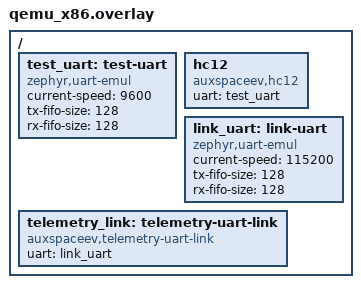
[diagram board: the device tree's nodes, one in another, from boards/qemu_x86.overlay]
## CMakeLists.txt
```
# Copyright (c) 2026 Auxspace e.V.
# SPDX-License-Identifier: Apache-2.0

cmake_minimum_required(VERSION 3.20.0)
find_package(Zephyr REQUIRED HINTS $ENV{ZEPHYR_BASE})
project(aurora_lib_telemetry_test)

FILE(GLOB app_sources src/*.c)
target_sources(app PRIVATE ${app_sources})
```

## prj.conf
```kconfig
CONFIG_ZTEST=y

CONFIG_AURORA_TELEMETRY=y
CONFIG_AURORA_TELEMETRY_UART_LINK=y

# Emulated UART for the HC-12 backend: keeps frame bytes off the real
# uart0 that carries ztest output. UART_EMUL depends on the broader
# EMUL framework, so both have to be enabled explicitly.
CONFIG_EMUL=y
CONFIG_UART_EMUL=y

# Pin the rate-limit window so the rate-limiter test exercises real
# state without being timing-fragile.
CONFIG_AURORA_TELEMETRY_HC12_MIN_INTERVAL_MS=50

# The state machine isn't actually used here, but the telemetry API
# pulls in sm_state / sm_inputs from its header.
CONFIG_AURORA_STATE_MACHINE=y
```

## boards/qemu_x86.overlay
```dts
/*
 * Copyright (c) 2026 Auxspace e.V.
 * SPDX-License-Identifier: Apache-2.0
 *
 * Route the HC-12 backend to Zephyr's emulated UART driver so the
 * TX worker's frame bytes don't collide with ztest output on the
 * real qemu uart0. The AT helper is not exercised here, so the SET
 * GPIO and uart_configure() support are intentionally absent.
 */

/ {
	test_uart: test-uart {
		compatible = "zephyr,uart-emul";
		status = "okay";
		current-speed = <9600>;
		tx-fifo-size = <128>;
		rx-fifo-size = <128>;
	};

	hc12: hc12 {
		compatible = "auxspaceev,hc12";
		uart = <&test_uart>;
		status = "okay";
	};

	/* A second emulated UART carries the plain uart-link backend, so a
	 * run exercises both instances of the uart-link engine at once and
	 * the dispatcher really does fan out to two independent transports
	 * - which is what a brain board with a local radio and an AUX-Tel
	 * relay above it looks like.
	 */
	link_uart: link-uart {
		compatible = "zephyr,uart-emul";
		status = "okay";
		current-speed = <115200>;
		tx-fifo-size = <128>;
		rx-fifo-size = <128>;
	};

	telemetry_link: telemetry-uart-link {
		compatible = "auxspaceev,telemetry-uart-link";
		uart = <&link_uart>;
		status = "okay";
	};
};
```

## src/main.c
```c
/**
 * @file main.c
 * @brief Unit tests for the telemetry dispatcher and its UART backends.
 *
 * Three suites:
 *   - format:    locks the telemetry wire frame byte-for-byte.
 *   - rate:      exercises the uart-link rate limiter (through the
 *                HC-12 backend, which is one instance of it).
 *   - dispatch:  verifies fan-out to multiple registered backends and
 *                the dispatcher's error aggregation, for SM updates
 *                and STATUS heartbeats.
 *
 * UART traffic from the worker thread is dumped into an emulated UART
 * rather than qemu's uart0, which carries ztest output. Tests never
 * read what leaves the wire. They verify counters and frame bytes
 * built by the shared helper directly.
 *
 * Copyright (c) 2025-2026 Auxspace e.V.
 *
 * SPDX-License-Identifier: Apache-2.0
 */

#include <string.h>

#include <zephyr/kernel.h>
#include <zephyr/sys/byteorder.h>
#include <zephyr/sys/crc.h>
#include <zephyr/ztest.h>

#include <aurora/lib/telemetry.h>
#include <aurora/lib/telemetry/wire.h>

/* ==========================================================
 *                     STUB BACKENDS
 * ==========================================================
 * Two stub backends are registered at link time alongside the HC-12
 * backend. Their behaviour is controlled by these globals so each
 * test can configure return codes independently.
 */
static int  stub_a_init_calls;
static int  stub_a_send_calls;
static int  stub_a_init_rc;
static int  stub_a_send_rc;

static int  stub_a_status_calls;
static struct telemetry_status stub_a_last_status;

static int  stub_b_init_calls;
static int  stub_b_send_calls;
static int  stub_b_init_rc;
static int  stub_b_send_rc;

static int stub_a_init(void) { stub_a_init_calls++; return stub_a_init_rc; }
static int stub_a_send(enum sm_state s, enum sm_type type,
		       const struct sm_inputs *in)
{
	ARG_UNUSED(s); ARG_UNUSED(in);
	stub_a_send_calls++;
	return stub_a_send_rc;
}

/* Only stub A implements send_status, so the dispatcher's NULL-slot
 * skip is exercised by stub B.
 */
static int stub_a_status(const struct telemetry_status *st)
{
	stub_a_status_calls++;
	stub_a_last_status = *st;
	return stub_a_send_rc;
}

static int stub_b_init(void) { stub_b_init_calls++; return stub_b_init_rc; }
static int stub_b_send(enum sm_state s, enum sm_type type,
		       const struct sm_inputs *in)
{
	ARG_UNUSED(s); ARG_UNUSED(in);
	stub_b_send_calls++;
	return stub_b_send_rc;
}

static const struct telemetry_backend_api stub_a_api = {
	.init = stub_a_init, .send_sm_update = stub_a_send,
	.send_status = stub_a_status,
};
static const struct telemetry_backend_api stub_b_api = {
	.init = stub_b_init, .send_sm_update = stub_b_send,
};

TELEMETRY_BACKEND_DEFINE(stub_a, &stub_a_api);
TELEMETRY_BACKEND_DEFINE(stub_b, &stub_b_api);

static void stub_reset(void)
{
	stub_a_init_calls = 0; stub_a_send_calls = 0;
	stub_a_init_rc = 0;    stub_a_send_rc = 0;
	stub_a_status_calls = 0;
	memset(&stub_a_last_status, 0, sizeof(stub_a_last_status));
	stub_b_init_calls = 0; stub_b_send_calls = 0;
	stub_b_init_rc = 0;    stub_b_send_rc = 0;
}

/* Minimal valid SM inputs for send_sm_update calls. */
static const struct sm_inputs DUMMY_INPUTS = {
	.armed = 1,
	.altitude = 100.0,
	.acceleration = 9.81,
	.accel_vert = 1.0,
	.velocity = 12.5,
	.orientation = { 0.1, 0.2, 0.3 },
};

/* Sleep long enough to clear any rate-limit window left over from a
 * previous test. CONFIG_AURORA_TELEMETRY_HC12_MIN_INTERVAL_MS=50.
 */
static inline void clear_rate_window(void)
{
	k_msleep(60);
}

/* ==========================================================
 *                     FORMAT SUITE
 * ==========================================================
 * Locks the HC-12 wire frame layout. Magic bytes, header field
 * positions, and the CRC algorithm are hardcoded *in the test*
 * rather than imported from the backend's headers. A silent change
 * to any of them in production must fail this suite.
 */

ZTEST(telemetry_wire_format, test_sm_update_frame_bytes)
{
	struct telemetry_wire_sm_update p = {
		.timestamp_ms = 0xDEADBEEF,
		.state        = 3,
		.armed        = 1,
		.reserved     = 0,
		.altitude     = 123.5,
		.acceleration = 9.81,
		.accel_vert   = -1.25,
		.velocity     = 42.0,
		.orientation  = { 0.5, -0.25, 1.0 },
	};

	uint8_t buf[128] = { 0 };
	size_t  n = telemetry_wire_finalise(buf, sizeof(buf), 0x01, &p,
					    (uint8_t)sizeof(p));

	/* Total = 2 magic + 1 type + 1 len + 64 payload + 2 CRC = 70.
	 * Payload = u32 + u8 + u8 + i16 + 4*f64 + 3*f64 = 64 bytes
	 * (packed, little-endian).
	 */
	zassert_equal(n, 70, "unexpected frame length: %zu", n);

	zassert_equal(buf[0], 0xA5, "magic0");
	zassert_equal(buf[1], 0x5A, "magic1");
	zassert_equal(buf[2], 0x01, "type=SM_UPDATE");
	zassert_equal(buf[3], 64,   "payload length byte");

	/* Payload is little-endian, packed. Check the first u32 by hand
	 * to lock byte order; trust memcpy semantics for the rest.
	 */
	zassert_equal(buf[4], 0xEF, "ts byte 0 (LE)");
	zassert_equal(buf[5], 0xBE, "ts byte 1");
	zassert_equal(buf[6], 0xAD, "ts byte 2");
	zassert_equal(buf[7], 0xDE, "ts byte 3");
	zassert_equal(buf[8], 3,    "state byte");
	zassert_equal(buf[9], 1,    "armed byte");

	/* CRC-16/CCITT (init 0xFFFF) over [type .. end of payload]. */
	uint16_t expected_crc = crc16_ccitt(0xFFFF, &buf[2], 1 + 1 + 64);
	uint16_t actual_crc   = sys_get_le16(&buf[68]);
	zassert_equal(actual_crc, expected_crc,
		      "CRC mismatch: got %04x want %04x",
		      actual_crc, expected_crc);
}

ZTEST(telemetry_wire_format, test_status_frame_bytes)
{
	struct telemetry_wire_status p = {
		.timestamp_ms = 0x01020304,
		.state        = 0,
		.sm_type      = 0,
		.flags        = 0x1B,
	};

	uint8_t buf[32] = { 0 };
	size_t  n = telemetry_wire_finalise(buf, sizeof(buf), 0x02, &p,
					    (uint8_t)sizeof(p));

	/* Total = 4 header + 8 payload + 2 CRC = 14. */
	zassert_equal(n, 14, "unexpected frame length: %zu", n);
	zassert_equal(buf[2], 0x02, "type=STATUS");
	zassert_equal(buf[3], 8,    "payload length byte");
	zassert_equal(buf[4], 0x04, "ts byte 0 (LE)");
	zassert_equal(buf[7], 0x01, "ts byte 3");
	zassert_equal(buf[8], 0,    "state byte");
	zassert_equal(buf[9], 0,    "sm_type byte");
	zassert_equal(buf[10], 0x1B, "flags byte");
	zassert_equal(buf[11], 0,   "reserved byte");

	/* Flag bits are decoded by offset on the ground: lock them. */
	zassert_equal(AURORA_TELEMETRY_WIRE_TYPE_STATUS, 0x02, "type id");
	zassert_equal(AURORA_TELEMETRY_WIRE_STATUS_ARMED, 0x01, "armed bit");
	zassert_equal(AURORA_TELEMETRY_WIRE_STATUS_IMU_OK, 0x02, "imu bit");
	zassert_equal(AURORA_TELEMETRY_WIRE_STATUS_BARO_OK, 0x04, "baro bit");
	zassert_equal(AURORA_TELEMETRY_WIRE_STATUS_CALIBRATED, 0x08, "cal bit");
	zassert_equal(AURORA_TELEMETRY_WIRE_STATUS_LOG_READY, 0x10, "log bit");

	zassert_true(telemetry_wire_validate(buf, n), "status frame validates");
}

ZTEST(telemetry_wire_format, test_buffer_too_small)
{
	struct telemetry_wire_sm_update p = { 0 };
	uint8_t small[10];

	zassert_equal(telemetry_wire_finalise(small, sizeof(small), 0x01, &p,
					      (uint8_t)sizeof(p)),
		      0, "should reject undersized buffer");
}

/* A zero-length payload is a valid frame: header plus CRC only. The
 * AUX-Tel relay forwards types it does not know, so an empty payload
 * has to survive the round trip.
 */
ZTEST(telemetry_wire_format, test_empty_payload_frame)
{
	uint8_t buf[16] = { 0 };
	size_t n = telemetry_wire_finalise(buf, sizeof(buf), 0x42, NULL, 0);

	zassert_equal(n, 6, "empty frame should be 6 bytes, got %zu", n);
	zassert_equal(buf[3], 0, "payload length byte");

	uint16_t expected = crc16_ccitt(0xFFFF, &buf[2], 2);

	zassert_equal(sys_get_le16(&buf[4]), expected, "CRC over type+len");
}

/* The relay reconstructs the CRC from the frame it received, so the
 * helper's span must match what a receiver computes by hand.
 */
ZTEST(telemetry_wire_format, test_crc_helper_matches_manual_span)
{
	struct telemetry_wire_sm_update p = { .timestamp_ms = 1, .state = 2 };
	uint8_t buf[128] = { 0 };
	size_t n = telemetry_wire_finalise(buf, sizeof(buf), 0x01, &p,
					   (uint8_t)sizeof(p));

	zassert_equal(n, 70, "frame length");
	zassert_equal(telemetry_wire_crc(buf, (uint8_t)sizeof(p)),
		      crc16_ccitt(0xFFFF, &buf[2], sizeof(p) + 2),
		      "helper span differs from the manual span");
}

/* telemetry_wire_validate() is the gate every frame arriving off the air
 * passes through, and it runs on a buffer straight out of a radio - so
 * the cases that matter are the malformed ones. A corrupt length byte in
 * particular must be caught before the CRC helper is allowed to read a
 * span derived from it.
 */
ZTEST(telemetry_wire_format, test_validate_accepts_a_built_frame)
{
	struct telemetry_wire_sm_update payload = {
		.timestamp_ms = 0x11223344,
		.state = 3,
		.armed = 1,
		.altitude = 1234.5,
	};
	uint8_t buf[128] = { 0 };
	size_t n = telemetry_wire_finalise(buf, sizeof(buf), 0x01, &payload,
					   (uint8_t)sizeof(payload));

	zassert_equal(n, 70, "frame length");
	zassert_true(telemetry_wire_validate(buf, n),
		     "a frame from telemetry_wire_finalise() must validate");
}

ZTEST(telemetry_wire_format, test_validate_accepts_empty_payload)
{
	uint8_t buf[16] = { 0 };
	size_t n = telemetry_wire_finalise(buf, sizeof(buf), 0x7F, NULL, 0);

	zassert_equal(n, AURORA_TELEMETRY_WIRE_OVERHEAD, "frame length");
	zassert_true(telemetry_wire_validate(buf, n), "empty payload frame");
}

ZTEST(telemetry_wire_format, test_validate_rejects_bad_magic)
{
	uint8_t buf[32] = { 0 };
	size_t n = telemetry_wire_finalise(buf, sizeof(buf), 0x01, "abcd", 4);

	buf[0] ^= 0xFF;
	zassert_false(telemetry_wire_validate(buf, n), "corrupt magic0");

	buf[0] ^= 0xFF;
	buf[1] ^= 0xFF;
	zassert_false(telemetry_wire_validate(buf, n), "corrupt magic1");
}

ZTEST(telemetry_wire_format, test_validate_rejects_length_disagreement)
{
	uint8_t buf[32] = { 0 };
	size_t n = telemetry_wire_finalise(buf, sizeof(buf), 0x01, "abcd", 4);

	/* The frame is intact, but the transport claims a different size:
	 * a truncated or padded packet.
	 */
	zassert_false(telemetry_wire_validate(buf, n - 1), "short packet");
	zassert_false(telemetry_wire_validate(buf, n + 1), "long packet");

	/* And the mirror image: the right byte count, but a len byte that
	 * disagrees with it. Left unchecked this is an out-of-bounds read.
	 */
	buf[3] = 200;
	zassert_false(telemetry_wire_validate(buf, n), "corrupt len byte");
}

ZTEST(telemetry_wire_format, test_validate_rejects_runts)
{
	uint8_t buf[AURORA_TELEMETRY_WIRE_OVERHEAD] = {
		AURORA_TELEMETRY_WIRE_MAGIC0, AURORA_TELEMETRY_WIRE_MAGIC1,
	};

	for (size_t len = 0; len < AURORA_TELEMETRY_WIRE_OVERHEAD; len++) {
		zassert_false(telemetry_wire_validate(buf, len),
			      "accepted a %zu byte packet", len);
	}

	zassert_false(telemetry_wire_validate(NULL, 70), "NULL frame");
}

ZTEST(telemetry_wire_format, test_validate_rejects_payload_corruption)
{
	uint8_t buf[32] = { 0 };
	size_t n = telemetry_wire_finalise(buf, sizeof(buf), 0x01, "abcd", 4);

	buf[AURORA_TELEMETRY_WIRE_HDR_LEN] ^= 0x01;
	zassert_false(telemetry_wire_validate(buf, n), "flipped payload bit");
}

ZTEST_SUITE(telemetry_wire_format, NULL, NULL, NULL, NULL, NULL);

/* ==========================================================
 *                     RATE LIMITER SUITE
 * ==========================================================
 * Exercises the uart-link rate limiter. The HC-12 backend is one
 * instance of that engine, and is the one wired up here; compiled with
 * CONFIG_AURORA_TELEMETRY_HC12_MIN_INTERVAL_MS=50.
 *
 * The dispatcher returns the first non-zero result from any backend.
 * Stubs A and B are silenced (rc=0) so the only path that can return
 * -EAGAIN is the HC-12 rate limiter.
 */

static void rate_before(void *fixture)
{
	ARG_UNUSED(fixture);
	stub_reset();
	(void)telemetry_init();
	clear_rate_window();
}

ZTEST(telemetry_rate, test_first_call_accepted)
{
	int rc = telemetry_send_sm_update(SM_IDLE, sm_get_type(), &DUMMY_INPUTS);

	zassert_equal(rc, 0, "first send should succeed, got %d", rc);
}

ZTEST(telemetry_rate, test_second_call_within_window_rejected)
{
	zassert_equal(telemetry_send_sm_update(SM_IDLE, sm_get_type(),
		      &DUMMY_INPUTS), 0, "first send");

	/* Burst the second one immediately. HC-12 should reject with
	 * -EAGAIN; the dispatcher returns the first non-zero rc.
	 */
	int rc = telemetry_send_sm_update(SM_IDLE, sm_get_type(),
		 &DUMMY_INPUTS);

	zassert_equal(rc, -EAGAIN,
		      "second send should be rate-limited, got %d", rc);

	/* Stubs are silent backends, they should *still* have received
	 * both calls (rate limiting is HC-12-local, not dispatcher-wide).
	 */
	zassert_equal(stub_a_send_calls, 2,
		      "stub_a should see both sends, got %d",
		      stub_a_send_calls);
}

ZTEST(telemetry_rate, test_recovery_after_window)
{
	zassert_equal(telemetry_send_sm_update(SM_IDLE, sm_get_type(),
		      &DUMMY_INPUTS), 0, "first send");
	zassert_equal(telemetry_send_sm_update(SM_IDLE, sm_get_type(),
		      &DUMMY_INPUTS), -EAGAIN, "second send");

	clear_rate_window();

	int rc = telemetry_send_sm_update(SM_IDLE, sm_get_type(),
					  &DUMMY_INPUTS);

	zassert_equal(rc, 0,
		      "send after window should succeed, got %d", rc);
}

/* A heartbeat must still go out on a link whose SM update stream keeps
 * the rate window permanently closed.
 */
ZTEST(telemetry_rate, test_status_bypasses_rate_limit)
{
	const struct telemetry_status st = { .state = SM_IDLE };

	zassert_equal(telemetry_send_sm_update(SM_IDLE, sm_get_type(),
		      &DUMMY_INPUTS), 0, "first send");

	int rc = telemetry_send_status(&st);

	zassert_equal(rc, 0, "status inside the SM window, got %d", rc);

	/* And it must not have opened a window of its own. */
	clear_rate_window();
	zassert_equal(telemetry_send_status(&st), 0, "status");
	zassert_equal(telemetry_send_sm_update(SM_IDLE, sm_get_type(),
		      &DUMMY_INPUTS), 0, "SM update after a status");
}

ZTEST_SUITE(telemetry_rate, NULL, NULL, rate_before, NULL, NULL);

/* ==========================================================
 *                     DISPATCH SUITE
 * ==========================================================
 * Verifies the dispatcher walks every registered backend and
 * aggregates errors correctly.
 */

static void dispatch_before(void *fixture)
{
	ARG_UNUSED(fixture);
	stub_reset();
	clear_rate_window();
}

ZTEST(telemetry_dispatch, test_init_fans_out_to_all_backends)
{
	int rc = telemetry_init();

	zassert_equal(rc, 0, "init with no backend errors");
	zassert_equal(stub_a_init_calls, 1,
		      "stub_a init called exactly once (got %d)",
		      stub_a_init_calls);
	zassert_equal(stub_b_init_calls, 1,
		      "stub_b init called exactly once (got %d)",
		      stub_b_init_calls);
}

ZTEST(telemetry_dispatch, test_init_reports_first_error_but_keeps_going)
{
	stub_a_init_rc = -EIO;
	stub_b_init_rc = 0;

	int rc = telemetry_init();

	zassert_equal(rc, -EIO,
		      "dispatcher should surface the first error, got %d",
		      rc);
	zassert_equal(stub_b_init_calls, 1,
		      "stub_b must still be called after stub_a failure");
}

ZTEST(telemetry_dispatch, test_send_fans_out_to_all_backends)
{
	(void)telemetry_init();
	stub_reset();
	clear_rate_window();

	int rc = telemetry_send_sm_update(SM_IDLE, sm_get_type(),
					  &DUMMY_INPUTS);

	zassert_equal(rc, 0, "all backends accepted");
	zassert_equal(stub_a_send_calls, 1,
		      "stub_a saw the send (got %d)", stub_a_send_calls);
	zassert_equal(stub_b_send_calls, 1,
		      "stub_b saw the send (got %d)", stub_b_send_calls);
}

ZTEST(telemetry_dispatch, test_send_surfaces_first_error)
{
	(void)telemetry_init();
	stub_reset();
	clear_rate_window();

	stub_a_send_rc = -EIO;
	stub_b_send_rc = -ENOSPC;

	int rc = telemetry_send_sm_update(SM_IDLE, sm_get_type(),
					  &DUMMY_INPUTS);

	zassert_true(rc == -EIO || rc == -ENOSPC,
		     "dispatcher returned an error from one of the stubs "
		     "(got %d)", rc);
	zassert_equal(stub_b_send_calls, 1,
		      "stub_b must run even after stub_a errors");
}

ZTEST(telemetry_dispatch, test_status_reaches_backends_with_the_hook)
{
	(void)telemetry_init();
	stub_reset();

	const struct telemetry_status st = {
		.state = SM_IDLE,
		.type = sm_get_type(),
		.imu_ok = true,
		.log_ready = true,
	};

	int rc = telemetry_send_status(&st);

	zassert_equal(rc, 0, "all backends accepted, got %d", rc);
	zassert_equal(stub_a_status_calls, 1, "stub_a saw the status");
	zassert_true(stub_a_last_status.imu_ok, "imu_ok carried through");
	zassert_false(stub_a_last_status.baro_ok, "baro_ok carried through");
	/* stub_b has no hook: skipped, not called through a NULL slot. */
	zassert_equal(stub_b_send_calls, 0, "stub_b untouched");
}

ZTEST(telemetry_dispatch, test_status_rejects_null)
{
	zassert_equal(telemetry_send_status(NULL), -EINVAL, "NULL status");
}

ZTEST_SUITE(telemetry_dispatch, NULL, NULL, dispatch_before, NULL, NULL);
```
